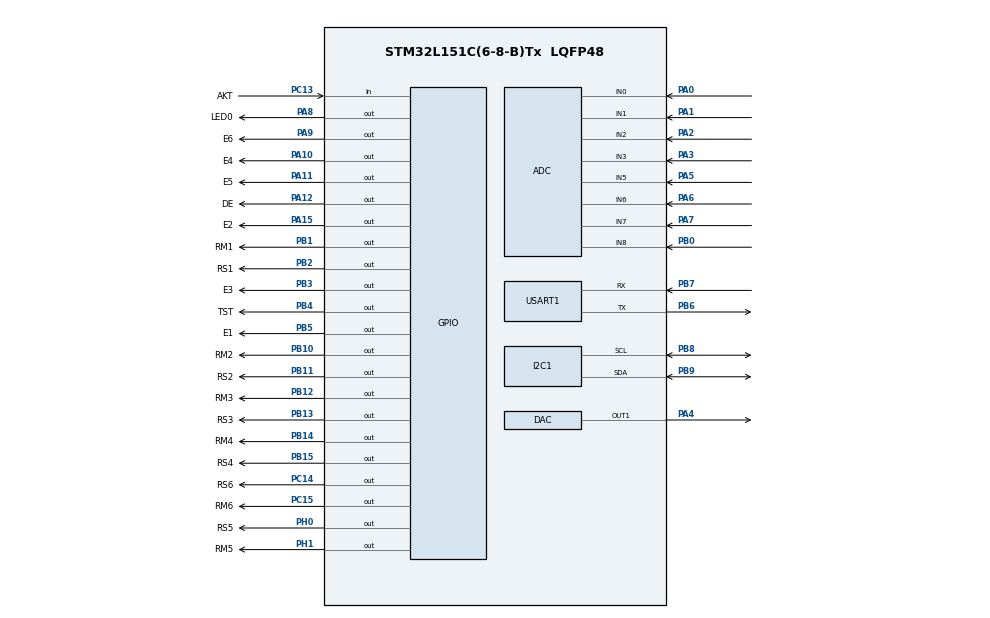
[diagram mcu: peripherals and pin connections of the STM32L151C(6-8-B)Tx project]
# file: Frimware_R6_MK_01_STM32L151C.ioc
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ADC.Channel-0\#ChannelRegularConversion=ADC_CHANNEL_2
ADC.Channel-1\#ChannelRegularConversion=ADC_CHANNEL_3
ADC.Channel-2\#ChannelRegularConversion=ADC_CHANNEL_5
ADC.Channel-3\#ChannelRegularConversion=ADC_CHANNEL_6
ADC.Channel-4\#ChannelRegularConversion=ADC_CHANNEL_7
ADC.Channel-5\#ChannelRegularConversion=ADC_CHANNEL_8
ADC.ClockPrescaler=ADC_CLOCK_ASYNC_DIV2
ADC.ContinuousConvMode=DISABLE
ADC.DMAContinuousRequests=ENABLE
ADC.DiscontinuousConvMode=DISABLE
ADC.ExternalTrigConv=ADC_EXTERNALTRIGCONV_T6_TRGO
ADC.InjNumberOfConversion=0
ADC.NbrOfConversion=6
ADC.NbrOfConversionFlag=1
ADC.Rank-0\#ChannelRegularConversion=1
ADC.Rank-1\#ChannelRegularConversion=2
ADC.Rank-2\#ChannelRegularConversion=3
ADC.Rank-3\#ChannelRegularConversion=4
ADC.Rank-4\#ChannelRegularConversion=5
ADC.Rank-5\#ChannelRegularConversion=6
ADC.SamplingTime-0\#ChannelRegularConversion=ADC_SAMPLETIME_24CYCLES
ADC.SamplingTime-1\#ChannelRegularConversion=ADC_SAMPLETIME_24CYCLES
ADC.SamplingTime-2\#ChannelRegularConversion=ADC_SAMPLETIME_24CYCLES
ADC.SamplingTime-3\#ChannelRegularConversion=ADC_SAMPLETIME_24CYCLES
ADC.SamplingTime-4\#ChannelRegularConversion=ADC_SAMPLETIME_24CYCLES
ADC.SamplingTime-5\#ChannelRegularConversion=ADC_SAMPLETIME_24CYCLES
ADC.ScanConvMode=ADC_SCAN_ENABLE
DAC.DAC_Trigger=DAC_TRIGGER_T7_TRGO
DAC.WaveGeneration=DISABLE
Dma.ADC.0.Direction=DMA_PERIPH_TO_MEMORY
Dma.ADC.0.Instance=DMA1_Channel1
Dma.ADC.0.MemDataAlignment=DMA_MDATAALIGN_HALFWORD
Dma.ADC.0.MemInc=DMA_MINC_ENABLE
Dma.ADC.0.Mode=DMA_CIRCULAR
Dma.ADC.0.PeriphDataAlignment=DMA_PDATAALIGN_HALFWORD
Dma.ADC.0.PeriphInc=DMA_PINC_DISABLE
Dma.ADC.0.Priority=DMA_PRIORITY_MEDIUM
Dma.DAC_CH1.1.Direction=DMA_MEMORY_TO_PERIPH
Dma.DAC_CH1.1.Instance=DMA1_Channel2
Dma.DAC_CH1.1.MemDataAlignment=DMA_MDATAALIGN_HALFWORD
Dma.DAC_CH1.1.MemInc=DMA_MINC_ENABLE
Dma.DAC_CH1.1.Mode=DMA_CIRCULAR
Dma.DAC_CH1.1.PeriphDataAlignment=DMA_PDATAALIGN_HALFWORD
Dma.DAC_CH1.1.PeriphInc=DMA_PINC_DISABLE
Dma.DAC_CH1.1.Priority=DMA_PRIORITY_MEDIUM
Dma.Request0=ADC
Dma.Request1=DAC_CH1
Mcu.Family=STM32L1
Mcu.Name=STM32L151C(6-8-B)Tx
Mcu.Package=LQFP48
NVIC.DMA1_Channel1_IRQn=true\:1\:0\:true\:false\:true\:true\:false
NVIC.DMA1_Channel2_IRQn=true\:0\:0\:false\:false\:true\:false\:true
NVIC.PriorityGroup=NVIC_PRIORITYGROUP_2
NVIC.USART1_IRQn=true\:0\:0\:true\:false\:false\:true\:false
PA0-WKUP1.Mode=IN0
PA0-WKUP1.Signal=ADC_IN0
PA1.Mode=IN1
PA1.Signal=ADC_IN1
PA10.GPIO_Label=E4
PA10.Signal=GPIO_Output
PA11.GPIO_Label=E5
PA11.Signal=GPIO_Output
PA12.GPIO_Label=DE
PA12.Signal=GPIO_Output
PA13.Mode=Serial_Wire
PA13.Signal=SYS_JTMS-SWDIO
PA14.Mode=Serial_Wire
PA14.Signal=SYS_JTCK-SWCLK
PA15.GPIO_Label=E2
PA15.Signal=GPIO_Output
PA2.Mode=IN2
PA2.Signal=ADC_IN2
PA3.Mode=IN3
PA3.Signal=ADC_IN3
PA4.Signal=COMP_DAC1_group
PA5.Mode=IN5
PA5.Signal=ADC_IN5
PA6.Mode=IN6
PA6.Signal=ADC_IN6
PA7.Mode=IN7
PA7.Signal=ADC_IN7
PA8.GPIO_Label=LED0
PA8.Signal=GPIO_Output
PA9.GPIO_Label=E6
PA9.Signal=GPIO_Output
PB0.Mode=IN8
PB0.Signal=ADC_IN8
PB1.GPIO_Label=RM1
PB1.Signal=GPIO_Output
PB10.GPIO_Label=RM2
PB10.Signal=GPIO_Output
PB11.GPIO_Label=RS2
PB11.Signal=GPIO_Output
PB12.GPIO_Label=RM3
PB12.Signal=GPIO_Output
PB13.GPIO_Label=RS3
PB13.Signal=GPIO_Output
PB14.GPIO_Label=RM4
PB14.Signal=GPIO_Output
PB15.GPIO_Label=RS4
PB15.Signal=GPIO_Output
PB2.GPIO_Label=RS1
PB2.Signal=GPIO_Output
PB3.GPIO_Label=E3
PB3.Signal=GPIO_Output
PB4.GPIO_Label=TST
PB4.Signal=GPIO_Output
PB5.GPIO_Label=E1
PB5.Signal=GPIO_Output
PB6.Mode=Asynchronous
PB6.Signal=USART1_TX
PB7.Mode=Asynchronous
PB7.Signal=USART1_RX
PB8.Mode=I2C
PB8.Signal=I2C1_SCL
PB9.Mode=I2C
PB9.Signal=I2C1_SDA
PC13-WKUP2.GPIO_Label=AKT
PC13-WKUP2.Signal=GPIO_Input
PC14-OSC32_IN.GPIO_Label=RS6
PC14-OSC32_IN.Signal=GPIO_Output
PC15-OSC32_OUT.GPIO_Label=RM6
PC15-OSC32_OUT.Signal=GPIO_Output
PH0-OSC_IN.GPIO_Label=RS5
PH0-OSC_IN.Signal=GPIO_Output
PH1-OSC_OUT.GPIO_Label=RM5
PH1-OSC_OUT.Signal=GPIO_Output
ProjectManager.HeapSize=0x100
ProjectManager.StackSize=0x200
ProjectManager.TargetToolchain=MDK-ARM V5
RCC.48MHZClocksFreq_Value=32000000
RCC.AHBFreq_Value=32000000
RCC.APB1Freq_Value=32000000
RCC.APB1TimFreq_Value=32000000
RCC.APB2Freq_Value=32000000
RCC.APB2TimFreq_Value=32000000
RCC.HCLKFreq_Value=32000000
RCC.HSE_VALUE=24000000
RCC.HSI_VALUE=16000000
RCC.LSE_VALUE=32768
RCC.MSI_VALUE=2097000
RCC.PLLMUL=RCC_PLL_MUL4
RCC.SYSCLKFreq_VALUE=32000000
RCC.SYSCLKSource=RCC_SYSCLKSOURCE_PLLCLK
RCC.VCOOutputFreq_Value=64000000
SH.COMP_DAC1_group.0=DAC_OUT1,DAC_OUT1
TIM6.Period=65535
TIM6.TIM_MasterOutputTrigger=TIM_TRGO_UPDATE
TIM7.Period=65535
TIM7.TIM_MasterOutputTrigger=TIM_TRGO_UPDATE
USART1.VirtualMode=VM_ASYNC
VP_TIM6_VS_ClockSourceINT.Mode=Enable_Timer
VP_TIM7_VS_ClockSourceINT.Mode=Enable_Timer
board=custom

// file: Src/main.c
/* USER CODE BEGIN Header */
/**
  ******************************************************************************
  * @file           : main.c
  * @brief          : Main program body
  ******************************************************************************
  ** This notice applies to any and all portions of this file
  * that are not between comment pairs USER CODE BEGIN and
  * USER CODE END. Other portions of this file, whether
  * inserted by the user or by software development tools
  * are owned by their respective copyright owners.
  *
  * COPYRIGHT(c) 2021 STMicroelectronics
  *
  * Redistribution and use in source and binary forms, with or without modification,
  * are permitted provided that the following conditions are met:
  *   1. Redistributions of source code must retain the above copyright notice,
  *      this list of conditions and the following disclaimer.
  *   2. Redistributions in binary form must reproduce the above copyright notice,
  *      this list of conditions and the following disclaimer in the documentation
  *      and/or other materials provided with the distribution.
  *   3. Neither the name of STMicroelectronics nor the names of its contributors
  *      may be used to endorse or promote products derived from this software
  *      without specific prior written permission.
  *
  * THIS SOFTWARE IS PROVIDED BY THE COPYRIGHT HOLDERS AND CONTRIBUTORS "AS IS"
  * AND ANY EXPRESS OR IMPLIED WARRANTIES, INCLUDING, BUT NOT LIMITED TO, THE
  * IMPLIED WARRANTIES OF MERCHANTABILITY AND FITNESS FOR A PARTICULAR PURPOSE ARE
  * DISCLAIMED. IN NO EVENT SHALL THE COPYRIGHT HOLDER OR CONTRIBUTORS BE LIABLE
  * FOR ANY DIRECT, INDIRECT, INCIDENTAL, SPECIAL, EXEMPLARY, OR CONSEQUENTIAL
  * DAMAGES (INCLUDING, BUT NOT LIMITED TO, PROCUREMENT OF SUBSTITUTE GOODS OR
  * SERVICES; LOSS OF USE, DATA, OR PROFITS; OR BUSINESS INTERRUPTION) HOWEVER
  * CAUSED AND ON ANY THEORY OF LIABILITY, WHETHER IN CONTRACT, STRICT LIABILITY,
  * OR TORT (INCLUDING NEGLIGENCE OR OTHERWISE) ARISING IN ANY WAY OUT OF THE USE
  * OF THIS SOFTWARE, EVEN IF ADVISED OF THE POSSIBILITY OF SUCH DAMAGE.
  *
  ******************************************************************************
  */
/* USER CODE END Header */

#include "main.h"

/* USER CODE BEGIN Includes */
#include "a_main.h"
#include "uart.h"
#include "main_logic.h"
#include "command.h"
/* USER CODE END Includes */

I2C_HandleTypeDef hi2c1;

void SystemClock_Config(void);
static void MX_GPIO_Init(void);
static void MX_DMA_Init(void);
static void MX_ADC_Init(void);
static void MX_DAC_Init(void);
static void MX_I2C1_Init(void);
static void MX_TIM7_Init(void);
static void MX_USART1_UART_Init(void);
static void MX_TIM6_Init(void);

int main(void)
{

  /* MCU Configuration--------------------------------------------------------*/

  /* Reset of all peripherals, Initializes the Flash interface and the Systick. */
  HAL_Init();

  /* Configure the system clock */
  SystemClock_Config();

  /* Initialize all configured peripherals */
  MX_GPIO_Init();
  MX_DMA_Init();
  MX_ADC_Init();
  MX_DAC_Init();
  MX_I2C1_Init();
  MX_TIM7_Init();
  MX_USART1_UART_Init();
  MX_TIM6_Init();
  /* USER CODE BEGIN 2 */
	User_init();
  initMainLogic();
  /* USER CODE END 2 */

  /* Infinite loop */
  while (1)
  {

    /* USER CODE BEGIN 3 */
//    uartPuts("test...\r");
//    LED0_TOG();
//    HAL_Delay(1000);
    //User_main();
    doCommand();
  }
  /* USER CODE END 3 */
}

void SystemClock_Config(void)
{

  LL_FLASH_Enable64bitAccess();

  LL_FLASH_SetLatency(LL_FLASH_LATENCY_1);

  if(LL_FLASH_GetLatency() != LL_FLASH_LATENCY_1)
  {
  Error_Handler();
  }
  LL_PWR_SetRegulVoltageScaling(LL_PWR_REGU_VOLTAGE_SCALE1);
  LL_RCC_HSI_Enable();

   /* Wait till HSI is ready */
  while(LL_RCC_HSI_IsReady() != 1)
  {

  }
  LL_RCC_HSI_SetCalibTrimming(16);
  LL_RCC_PLL_ConfigDomain_SYS(LL_RCC_PLLSOURCE_HSI, LL_RCC_PLL_MUL_4, LL_RCC_PLL_DIV_2);
  LL_RCC_PLL_Enable();

   /* Wait till PLL is ready */
  while(LL_RCC_PLL_IsReady() != 1)
  {

  }
  LL_RCC_SetAHBPrescaler(LL_RCC_SYSCLK_DIV_1);
  LL_RCC_SetAPB1Prescaler(LL_RCC_APB1_DIV_1);
  LL_RCC_SetAPB2Prescaler(LL_RCC_APB2_DIV_1);
  LL_RCC_SetSysClkSource(LL_RCC_SYS_CLKSOURCE_PLL);

   /* Wait till System clock is ready */
  while(LL_RCC_GetSysClkSource() != LL_RCC_SYS_CLKSOURCE_STATUS_PLL)
  {

  }
  LL_SetSystemCoreClock(32000000);

   /* Update the time base */
  if (HAL_InitTick (TICK_INT_PRIORITY) != HAL_OK)
  {
    Error_Handler();
  };
}

static void MX_ADC_Init(void)
{

  LL_ADC_CommonInitTypeDef ADC_CommonInitStruct = {0};
  LL_ADC_InitTypeDef ADC_InitStruct = {0};
  LL_ADC_REG_InitTypeDef ADC_REG_InitStruct = {0};

  LL_GPIO_InitTypeDef GPIO_InitStruct = {0};

  /* Peripheral clock enable */
  LL_APB2_GRP1_EnableClock(LL_APB2_GRP1_PERIPH_ADC1);

  LL_AHB1_GRP1_EnableClock(LL_AHB1_GRP1_PERIPH_GPIOA);
  LL_AHB1_GRP1_EnableClock(LL_AHB1_GRP1_PERIPH_GPIOB);
  /**ADC GPIO Configuration
  PA0-WKUP1   ------> ADC_IN0
  PA1   ------> ADC_IN1
  PA2   ------> ADC_IN2
  PA3   ------> ADC_IN3
  PA5   ------> ADC_IN5
  PA6   ------> ADC_IN6
  PA7   ------> ADC_IN7
  PB0   ------> ADC_IN8
  */
  GPIO_InitStruct.Pin = LL_GPIO_PIN_0;
  GPIO_InitStruct.Mode = LL_GPIO_MODE_ANALOG;
  GPIO_InitStruct.Pull = LL_GPIO_PULL_NO;
  LL_GPIO_Init(GPIOA, &GPIO_InitStruct);

  GPIO_InitStruct.Pin = LL_GPIO_PIN_1;
  GPIO_InitStruct.Mode = LL_GPIO_MODE_ANALOG;
  GPIO_InitStruct.Pull = LL_GPIO_PULL_NO;
  LL_GPIO_Init(GPIOA, &GPIO_InitStruct);

  GPIO_InitStruct.Pin = LL_GPIO_PIN_2;
  GPIO_InitStruct.Mode = LL_GPIO_MODE_ANALOG;
  GPIO_InitStruct.Pull = LL_GPIO_PULL_NO;
  LL_GPIO_Init(GPIOA, &GPIO_InitStruct);

  GPIO_InitStruct.Pin = LL_GPIO_PIN_3;
  GPIO_InitStruct.Mode = LL_GPIO_MODE_ANALOG;
  GPIO_InitStruct.Pull = LL_GPIO_PULL_NO;
  LL_GPIO_Init(GPIOA, &GPIO_InitStruct);

  GPIO_InitStruct.Pin = LL_GPIO_PIN_5;
  GPIO_InitStruct.Mode = LL_GPIO_MODE_ANALOG;
  GPIO_InitStruct.Pull = LL_GPIO_PULL_NO;
  LL_GPIO_Init(GPIOA, &GPIO_InitStruct);

  GPIO_InitStruct.Pin = LL_GPIO_PIN_6;
  GPIO_InitStruct.Mode = LL_GPIO_MODE_ANALOG;
  GPIO_InitStruct.Pull = LL_GPIO_PULL_NO;
  LL_GPIO_Init(GPIOA, &GPIO_InitStruct);

  GPIO_InitStruct.Pin = LL_GPIO_PIN_7;
  GPIO_InitStruct.Mode = LL_GPIO_MODE_ANALOG;
  GPIO_InitStruct.Pull = LL_GPIO_PULL_NO;
  LL_GPIO_Init(GPIOA, &GPIO_InitStruct);

  GPIO_InitStruct.Pin = LL_GPIO_PIN_0;
  GPIO_InitStruct.Mode = LL_GPIO_MODE_ANALOG;
  GPIO_InitStruct.Pull = LL_GPIO_PULL_NO;
  LL_GPIO_Init(GPIOB, &GPIO_InitStruct);

  /* ADC DMA Init */

  /* ADC Init */
  LL_DMA_SetDataTransferDirection(DMA1, LL_DMA_CHANNEL_1, LL_DMA_DIRECTION_PERIPH_TO_MEMORY);

  LL_DMA_SetChannelPriorityLevel(DMA1, LL_DMA_CHANNEL_1, LL_DMA_PRIORITY_MEDIUM);

  LL_DMA_SetMode(DMA1, LL_DMA_CHANNEL_1, LL_DMA_MODE_CIRCULAR);

  LL_DMA_SetPeriphIncMode(DMA1, LL_DMA_CHANNEL_1, LL_DMA_PERIPH_NOINCREMENT);

  LL_DMA_SetMemoryIncMode(DMA1, LL_DMA_CHANNEL_1, LL_DMA_MEMORY_INCREMENT);

  LL_DMA_SetPeriphSize(DMA1, LL_DMA_CHANNEL_1, LL_DMA_PDATAALIGN_HALFWORD);

  LL_DMA_SetMemorySize(DMA1, LL_DMA_CHANNEL_1, LL_DMA_MDATAALIGN_HALFWORD);

  /** Configure the global features of the ADC (Clock, Resolution, Data Alignment and number of conversion)
  */
  ADC_CommonInitStruct.CommonClock = LL_ADC_CLOCK_ASYNC_DIV2;
  LL_ADC_CommonInit(__LL_ADC_COMMON_INSTANCE(ADC1), &ADC_CommonInitStruct);
  ADC_InitStruct.Resolution = LL_ADC_RESOLUTION_12B;
  ADC_InitStruct.DataAlignment = LL_ADC_DATA_ALIGN_RIGHT;
  ADC_InitStruct.LowPowerMode = LL_ADC_LP_AUTOWAIT_NONE|LL_ADC_LP_AUTOPOWEROFF_NONE;
  ADC_InitStruct.SequencersScanMode = LL_ADC_SEQ_SCAN_ENABLE;
  LL_ADC_Init(ADC1, &ADC_InitStruct);
  ADC_REG_InitStruct.TriggerSource = LL_ADC_REG_TRIG_EXT_TIM6_TRGO;
  ADC_REG_InitStruct.SequencerLength = LL_ADC_REG_SEQ_SCAN_ENABLE_6RANKS;
  ADC_REG_InitStruct.SequencerDiscont = LL_ADC_REG_SEQ_DISCONT_DISABLE;
  ADC_REG_InitStruct.ContinuousMode = LL_ADC_REG_CONV_SINGLE;
  ADC_REG_InitStruct.DMATransfer = LL_ADC_REG_DMA_TRANSFER_UNLIMITED;
  LL_ADC_REG_Init(ADC1, &ADC_REG_InitStruct);
  LL_ADC_REG_SetFlagEndOfConversion(ADC1, LL_ADC_REG_FLAG_EOC_SEQUENCE_CONV);
  LL_ADC_REG_StartConversionExtTrig(ADC1, LL_ADC_REG_TRIG_EXT_RISING);
  /** Configure Regular Channel
  */
  LL_ADC_REG_SetSequencerRanks(ADC1, LL_ADC_REG_RANK_1, LL_ADC_CHANNEL_2);
  LL_ADC_SetChannelSamplingTime(ADC1, LL_ADC_CHANNEL_2, LL_ADC_SAMPLINGTIME_24CYCLES);
  /** Configure Regular Channel
  */
  LL_ADC_REG_SetSequencerRanks(ADC1, LL_ADC_REG_RANK_2, LL_ADC_CHANNEL_3);
  LL_ADC_SetChannelSamplingTime(ADC1, LL_ADC_CHANNEL_3, LL_ADC_SAMPLINGTIME_24CYCLES);
  /** Configure Regular Channel
  */
  LL_ADC_REG_SetSequencerRanks(ADC1, LL_ADC_REG_RANK_3, LL_ADC_CHANNEL_5);
  LL_ADC_SetChannelSamplingTime(ADC1, LL_ADC_CHANNEL_5, LL_ADC_SAMPLINGTIME_24CYCLES);
  /** Configure Regular Channel
  */
  LL_ADC_REG_SetSequencerRanks(ADC1, LL_ADC_REG_RANK_4, LL_ADC_CHANNEL_6);
  LL_ADC_SetChannelSamplingTime(ADC1, LL_ADC_CHANNEL_6, LL_ADC_SAMPLINGTIME_24CYCLES);
  /** Configure Regular Channel
  */
  LL_ADC_REG_SetSequencerRanks(ADC1, LL_ADC_REG_RANK_5, LL_ADC_CHANNEL_7);
  LL_ADC_SetChannelSamplingTime(ADC1, LL_ADC_CHANNEL_7, LL_ADC_SAMPLINGTIME_24CYCLES);
  /** Configure Regular Channel
  */
  LL_ADC_REG_SetSequencerRanks(ADC1, LL_ADC_REG_RANK_6, LL_ADC_CHANNEL_8);
  LL_ADC_SetChannelSamplingTime(ADC1, LL_ADC_CHANNEL_8, LL_ADC_SAMPLINGTIME_24CYCLES);

}

static void MX_DAC_Init(void)
{

  LL_DAC_InitTypeDef DAC_InitStruct = {0};

  LL_GPIO_InitTypeDef GPIO_InitStruct = {0};

  /* Peripheral clock enable */
  LL_APB1_GRP1_EnableClock(LL_APB1_GRP1_PERIPH_DAC1);

  LL_AHB1_GRP1_EnableClock(LL_AHB1_GRP1_PERIPH_GPIOA);
  /**DAC GPIO Configuration
  PA4   ------> DAC_OUT1
  */
  GPIO_InitStruct.Pin = LL_GPIO_PIN_4;
  GPIO_InitStruct.Mode = LL_GPIO_MODE_ANALOG;
  GPIO_InitStruct.Pull = LL_GPIO_PULL_NO;
  LL_GPIO_Init(GPIOA, &GPIO_InitStruct);

  /* DAC DMA Init */

  /* DAC_CH1 Init */
  LL_DMA_SetDataTransferDirection(DMA1, LL_DMA_CHANNEL_2, LL_DMA_DIRECTION_MEMORY_TO_PERIPH);

  LL_DMA_SetChannelPriorityLevel(DMA1, LL_DMA_CHANNEL_2, LL_DMA_PRIORITY_MEDIUM);

  LL_DMA_SetMode(DMA1, LL_DMA_CHANNEL_2, LL_DMA_MODE_CIRCULAR);

  LL_DMA_SetPeriphIncMode(DMA1, LL_DMA_CHANNEL_2, LL_DMA_PERIPH_NOINCREMENT);

  LL_DMA_SetMemoryIncMode(DMA1, LL_DMA_CHANNEL_2, LL_DMA_MEMORY_INCREMENT);

  LL_DMA_SetPeriphSize(DMA1, LL_DMA_CHANNEL_2, LL_DMA_PDATAALIGN_HALFWORD);

  LL_DMA_SetMemorySize(DMA1, LL_DMA_CHANNEL_2, LL_DMA_MDATAALIGN_HALFWORD);

  /** DAC channel OUT1 config
  */
  DAC_InitStruct.TriggerSource = LL_DAC_TRIG_EXT_TIM7_TRGO;
  DAC_InitStruct.WaveAutoGeneration = LL_DAC_WAVE_AUTO_GENERATION_NONE;
  DAC_InitStruct.OutputBuffer = LL_DAC_OUTPUT_BUFFER_ENABLE;
  LL_DAC_Init(DAC, LL_DAC_CHANNEL_1, &DAC_InitStruct);

}

static void MX_I2C1_Init(void)
{

  hi2c1.Instance = I2C1;
  hi2c1.Init.ClockSpeed = 100000;
  hi2c1.Init.DutyCycle = I2C_DUTYCYCLE_2;
  hi2c1.Init.OwnAddress1 = 0;
  hi2c1.Init.AddressingMode = I2C_ADDRESSINGMODE_7BIT;
  hi2c1.Init.DualAddressMode = I2C_DUALADDRESS_DISABLE;
  hi2c1.Init.OwnAddress2 = 0;
  hi2c1.Init.GeneralCallMode = I2C_GENERALCALL_DISABLE;
  hi2c1.Init.NoStretchMode = I2C_NOSTRETCH_DISABLE;
  if (HAL_I2C_Init(&hi2c1) != HAL_OK)
  {
    Error_Handler();
  }

}

static void MX_TIM6_Init(void)
{

  LL_TIM_InitTypeDef TIM_InitStruct = {0};

  /* Peripheral clock enable */
  LL_APB1_GRP1_EnableClock(LL_APB1_GRP1_PERIPH_TIM6);

  TIM_InitStruct.Prescaler = 0;
  TIM_InitStruct.CounterMode = LL_TIM_COUNTERMODE_UP;
  TIM_InitStruct.Autoreload = 65535;
  LL_TIM_Init(TIM6, &TIM_InitStruct);
  LL_TIM_DisableARRPreload(TIM6);
  LL_TIM_SetTriggerOutput(TIM6, LL_TIM_TRGO_UPDATE);
  LL_TIM_DisableMasterSlaveMode(TIM6);

}

static void MX_TIM7_Init(void)
{

  LL_TIM_InitTypeDef TIM_InitStruct = {0};

  /* Peripheral clock enable */
  LL_APB1_GRP1_EnableClock(LL_APB1_GRP1_PERIPH_TIM7);

  TIM_InitStruct.Prescaler = 0;
  TIM_InitStruct.CounterMode = LL_TIM_COUNTERMODE_UP;
  TIM_InitStruct.Autoreload = 65535;
  LL_TIM_Init(TIM7, &TIM_InitStruct);
  LL_TIM_DisableARRPreload(TIM7);
  LL_TIM_SetTriggerOutput(TIM7, LL_TIM_TRGO_UPDATE);
  LL_TIM_DisableMasterSlaveMode(TIM7);

}

static void MX_USART1_UART_Init(void)
{

  LL_USART_InitTypeDef USART_InitStruct = {0};

  LL_GPIO_InitTypeDef GPIO_InitStruct = {0};

  /* Peripheral clock enable */
  LL_APB2_GRP1_EnableClock(LL_APB2_GRP1_PERIPH_USART1);

  LL_AHB1_GRP1_EnableClock(LL_AHB1_GRP1_PERIPH_GPIOB);
  /**USART1 GPIO Configuration
  PB6   ------> USART1_TX
  PB7   ------> USART1_RX
  */
  GPIO_InitStruct.Pin = LL_GPIO_PIN_6;
  GPIO_InitStruct.Mode = LL_GPIO_MODE_ALTERNATE;
  GPIO_InitStruct.Speed = LL_GPIO_SPEED_FREQ_VERY_HIGH;
  GPIO_InitStruct.OutputType = LL_GPIO_OUTPUT_PUSHPULL;
  GPIO_InitStruct.Pull = LL_GPIO_PULL_NO;
  GPIO_InitStruct.Alternate = LL_GPIO_AF_7;
  LL_GPIO_Init(GPIOB, &GPIO_InitStruct);

  GPIO_InitStruct.Pin = LL_GPIO_PIN_7;
  GPIO_InitStruct.Mode = LL_GPIO_MODE_ALTERNATE;
  GPIO_InitStruct.Speed = LL_GPIO_SPEED_FREQ_VERY_HIGH;
  GPIO_InitStruct.OutputType = LL_GPIO_OUTPUT_PUSHPULL;
  GPIO_InitStruct.Pull = LL_GPIO_PULL_NO;
  GPIO_InitStruct.Alternate = LL_GPIO_AF_7;
  LL_GPIO_Init(GPIOB, &GPIO_InitStruct);

  /* USART1 interrupt Init */
  NVIC_SetPriority(USART1_IRQn, NVIC_EncodePriority(NVIC_GetPriorityGrouping(),0, 0));
  NVIC_EnableIRQ(USART1_IRQn);

  USART_InitStruct.BaudRate = 115200;
  USART_InitStruct.DataWidth = LL_USART_DATAWIDTH_8B;
  USART_InitStruct.StopBits = LL_USART_STOPBITS_1;
  USART_InitStruct.Parity = LL_USART_PARITY_NONE;
  USART_InitStruct.TransferDirection = LL_USART_DIRECTION_TX_RX;
  USART_InitStruct.HardwareFlowControl = LL_USART_HWCONTROL_NONE;
  USART_InitStruct.OverSampling = LL_USART_OVERSAMPLING_16;
  LL_USART_Init(USART1, &USART_InitStruct);
  LL_USART_DisableIT_CTS(USART1);
  LL_USART_ConfigAsyncMode(USART1);
  LL_USART_Enable(USART1);

}

static void MX_DMA_Init(void)
{

  /* Init with LL driver */
  /* DMA controller clock enable */
  LL_AHB1_GRP1_EnableClock(LL_AHB1_GRP1_PERIPH_DMA1);

  /* DMA interrupt init */
  /* DMA1_Channel1_IRQn interrupt configuration */
  NVIC_SetPriority(DMA1_Channel1_IRQn, NVIC_EncodePriority(NVIC_GetPriorityGrouping(),1, 0));
  NVIC_EnableIRQ(DMA1_Channel1_IRQn);
  /* DMA1_Channel2_IRQn interrupt configuration */
  NVIC_SetPriority(DMA1_Channel2_IRQn, NVIC_EncodePriority(NVIC_GetPriorityGrouping(),0, 0));
  NVIC_EnableIRQ(DMA1_Channel2_IRQn);

}

static void MX_GPIO_Init(void)
{
  GPIO_InitTypeDef GPIO_InitStruct = {0};

  /* GPIO Ports Clock Enable */
  __HAL_RCC_GPIOC_CLK_ENABLE();
  __HAL_RCC_GPIOH_CLK_ENABLE();
  __HAL_RCC_GPIOA_CLK_ENABLE();
  __HAL_RCC_GPIOB_CLK_ENABLE();

  /*Configure GPIO pin Output Level */
  HAL_GPIO_WritePin(GPIOC, RS6_Pin|RM6_Pin, GPIO_PIN_RESET);

  /*Configure GPIO pin Output Level */
  HAL_GPIO_WritePin(GPIOH, RS5_Pin|RM5_Pin, GPIO_PIN_RESET);

  /*Configure GPIO pin Output Level */
  HAL_GPIO_WritePin(GPIOB, RM1_Pin|RS1_Pin|RM2_Pin|RS2_Pin
                          |RM3_Pin|RS3_Pin|RM4_Pin|RS4_Pin
                          |E3_Pin|TST_Pin|E1_Pin, GPIO_PIN_RESET);

  /*Configure GPIO pin Output Level */
  HAL_GPIO_WritePin(GPIOA, LED0_Pin|E6_Pin|E4_Pin|E5_Pin
                          |DE_Pin|E2_Pin, GPIO_PIN_RESET);

  /*Configure GPIO pin : AKT_Pin */
  GPIO_InitStruct.Pin = AKT_Pin;
  GPIO_InitStruct.Mode = GPIO_MODE_INPUT;
  GPIO_InitStruct.Pull = GPIO_NOPULL;
  HAL_GPIO_Init(AKT_GPIO_Port, &GPIO_InitStruct);

  /*Configure GPIO pins : RS6_Pin RM6_Pin */
  GPIO_InitStruct.Pin = RS6_Pin|RM6_Pin;
  GPIO_InitStruct.Mode = GPIO_MODE_OUTPUT_PP;
  GPIO_InitStruct.Pull = GPIO_NOPULL;
  GPIO_InitStruct.Speed = GPIO_SPEED_FREQ_LOW;
  HAL_GPIO_Init(GPIOC, &GPIO_InitStruct);

  /*Configure GPIO pins : RS5_Pin RM5_Pin */
  GPIO_InitStruct.Pin = RS5_Pin|RM5_Pin;
  GPIO_InitStruct.Mode = GPIO_MODE_OUTPUT_PP;
  GPIO_InitStruct.Pull = GPIO_NOPULL;
  GPIO_InitStruct.Speed = GPIO_SPEED_FREQ_LOW;
  HAL_GPIO_Init(GPIOH, &GPIO_InitStruct);

  /*Configure GPIO pins : RM1_Pin RS1_Pin RM2_Pin RS2_Pin
                           RM3_Pin RS3_Pin RM4_Pin RS4_Pin
                           E3_Pin TST_Pin E1_Pin */
  GPIO_InitStruct.Pin = RM1_Pin|RS1_Pin|RM2_Pin|RS2_Pin
                          |RM3_Pin|RS3_Pin|RM4_Pin|RS4_Pin
                          |E3_Pin|TST_Pin|E1_Pin;
  GPIO_InitStruct.Mode = GPIO_MODE_OUTPUT_PP;
  GPIO_InitStruct.Pull = GPIO_NOPULL;
  GPIO_InitStruct.Speed = GPIO_SPEED_FREQ_LOW;
  HAL_GPIO_Init(GPIOB, &GPIO_InitStruct);

  /*Configure GPIO pins : LED0_Pin E6_Pin E4_Pin E5_Pin
                           DE_Pin E2_Pin */
  GPIO_InitStruct.Pin = LED0_Pin|E6_Pin|E4_Pin|E5_Pin
                          |DE_Pin|E2_Pin;
  GPIO_InitStruct.Mode = GPIO_MODE_OUTPUT_PP;
  GPIO_InitStruct.Pull = GPIO_NOPULL;
  GPIO_InitStruct.Speed = GPIO_SPEED_FREQ_LOW;
  HAL_GPIO_Init(GPIOA, &GPIO_InitStruct);

}

void Error_Handler(void)
{
}

/************************ (C) COPYRIGHT STMicroelectronics *****END OF FILE****/
